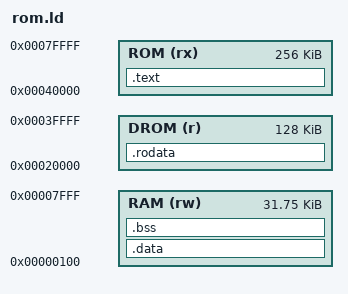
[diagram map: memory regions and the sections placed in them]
ENTRY(_start)
MEMORY {
  RAM (rw) : ORIGIN = 0x100, LENGTH = 0x7F00
  DROM (r) : ORIGIN = 0x20000, LENGTH = 128K
  ROM (rx) : ORIGIN = 0x40000, LENGTH = 256K
}
SECTIONS {
  .text : { *(.text.init) *(.text .text.*) } > ROM
  .rodata : { *(.rodata .rodata.* .srodata .srodata.*) } > DROM
  .data : { *(.data .data.* .sdata .sdata.*) } > RAM
  .bss (NOLOAD) : { *(.bss .bss.* .sbss .sbss.*) *(COMMON) } > RAM
  /DISCARD/ : { *(.comment) *(.eh_frame*) }
}
